AUTOSAR XML (schema 4-0-3)
package /AComp
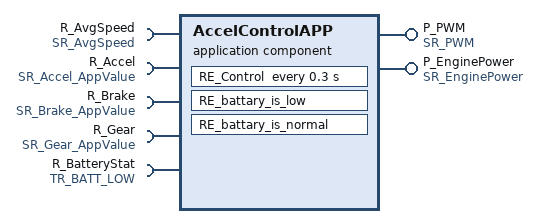
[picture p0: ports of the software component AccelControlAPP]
  application sw component type AccelControlAPP
    require port R_AvgSpeed: required-interface=SR_AvgSpeed
    provide port P_PWM: provided-interface=SR_PWM
    provide port P_EnginePower: provided-interface=SR_EnginePower
    4 x require port:
      R_Accel: required-interface=SR_Accel_AppValue
      R_Brake: required-interface=SR_Brake_AppValue
      R_Gear: required-interface=SR_Gear_AppValue
      R_BatteryStat: required-interface=TR_BATT_LOW
    behavior IB_AccelControlAPP
      timing event TimingEvent_0: start-on-event=RE_Control, period=0.3
      external trigger occurred event ExternalTriggerOccurredEvent_0: start-on-event=RE_battary_is_normal, trigger=R_BatteryStat.normal
      external trigger occurred event ExternalTriggerOccurredEvent_1: start-on-event=RE_battary_is_low, trigger=R_BatteryStat.low
      runnable RE_Control: symbol=RE_Control_func
        data-receive-point-by-values:
          4 x access:
            DRPV_gear_value_0: accessed-variable=R_Gear.gear_value
            DRPV_accel_value_0: accessed-variable=R_Accel.accel_value
            DRPV_brake_value_0: accessed-variable=R_Brake.brake_value
            DRPV_avg_speed_data_0: accessed-variable=R_AvgSpeed.avg_speed_data
        data-send-points:
          access DSP_powerValue_0: accessed-variable=P_EnginePower.powerValue
          access DSP_pwm_data_0: accessed-variable=P_PWM.pwm_data
      runnable RE_battary_is_low: symbol=RE_battary_is_low_func
      runnable RE_battary_is_normal: symbol=RE_battary_is_normal_func
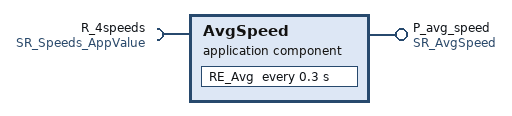
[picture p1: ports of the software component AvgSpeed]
  application sw component type AvgSpeed
    require port R_4speeds: required-interface=SR_Speeds_AppValue
    provide port P_avg_speed: provided-interface=SR_AvgSpeed
    behavior IB_AvgSpeed
      timing event TimingEvent_0: start-on-event=RE_Avg, period=0.3
      runnable RE_Avg: symbol=RE_Avg_func
        data-receive-point-by-values:
          4 x access:
            DRPV_frontleft_0: accessed-variable=R_4speeds.frontleft
            DRPV_frontright_0: accessed-variable=R_4speeds.frontright
            DRPV_backleft_0: accessed-variable=R_4speeds.backleft
            DRPV_backright_0: accessed-variable=R_4speeds.backright
        data-send-points:
          access DSP_avg_speed_data_0: accessed-variable=P_avg_speed.avg_speed_data
  sender receiver interface SR_AvgSpeed
    data avg_speed_data: type=float64
  sender receiver interface SR_Pedal_Accel
    data pedal_accel: type=uint16
  sender receiver interface SR_Pedal_Brake
    data pedal_brake: type=uint16
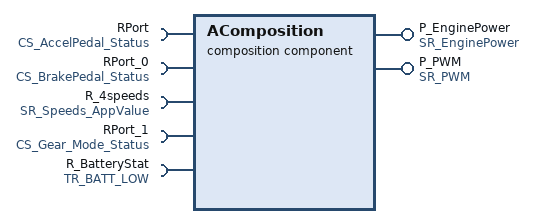
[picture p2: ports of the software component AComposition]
  composition sw component type AComposition
    4 x require port:
      RPort: required-interface=CS_AccelPedal_Status
      RPort_0: required-interface=CS_BrakePedal_Status
      R_4speeds: required-interface=SR_Speeds_AppValue
      RPort_1: required-interface=CS_Gear_Mode_Status
    provide port P_EnginePower: provided-interface=SR_EnginePower
    provide port P_PWM: provided-interface=SR_PWM
    require port R_BatteryStat: required-interface=TR_BATT_LOW
    5 x component:
      CPT_AvgSpeed: type=AvgSpeed
      CPT_AccelControlAPP: type=AccelControlAPP
      CPT_GearModeSen: type=GearModeSen
      CPT_AccelPedalSen: type=AccelPedalSen
      CPT_BrakePedalSen: type=BrakePedalSen
    connect CPT_AvgSpeed.P_avg_speed -> CPT_AccelControlAPP.R_AvgSpeed
    connect CPT_BrakePedalSen.toApp_PPort -> CPT_AccelControlAPP.R_Brake
    connect CPT_GearModeSen.toApp_PPort -> CPT_AccelControlAPP.R_Gear
    connect CPT_AccelPedalSen.toApp_PPort -> CPT_AccelControlAPP.R_Accel
    delegate CPT_AccelPedalSen.RPort <-> outer port RPort
    delegate CPT_BrakePedalSen.RPort <-> outer port RPort_0
    delegate CPT_AvgSpeed.R_4speeds <-> outer port AComposition/R_4speeds
    delegate CPT_GearModeSen.RPort <-> outer port RPort_1
    delegate CPT_AccelControlAPP.P_EnginePower <-> outer port AComposition/P_EnginePower
    delegate CPT_AccelControlAPP.P_PWM <-> outer port AComposition/P_PWM
    delegate CPT_AccelControlAPP.R_BatteryStat <-> outer port AComposition/R_BatteryStat
  sender receiver interface SR_BrakePower
    data brakepower: type=uint16
